# soc_debugss_dssm_mdb_secure register map
Vendor: Texas Instruments
Peripheral module from a debugger description file (folder CC35X1E).
Registers are 32-bit, read-only, reset 0x0 unless marked. A register's access mark holds for its fields unless they carry their own. Offsets are as the file gives them; lines under a group give offsets from that group; [hi:lo] are bit positions; {n}, {i} and the like mark numbered series; 'fields as' and 'values as' point back to an identical list; <NAME> marks a mode.

## soc_debugss_dssm_mdb_secure
0x20 dssm_iidx — This register provides the highest priority enabled interrupt index. FFh means no event pending. Interrupt 0h is the highest priority, 1h next highest, and FEh is the least priority. The priority order is fixed. However, users can implement their own prioritization schemes using other registers that expose the full set of interrupts that have occurred. On each read, only one interrupt is indicated. On a read, the current interrupt (highest priority) is automatically cleared by the hardware and the corresponding interrupt flag in the RIS and MIS are cleared as well. After a read from the CPU (not from the debug interface), the register must be updated with the next highest priority interrupt, if none are pending, then it displays FFh.
  [1:0] STAT — Interrupt index status
    0=NO_INTR (No pending interrupt request); 1=MSG_PEND (TX interrupt); 2=MSG_TAKEN (RX interrupt)
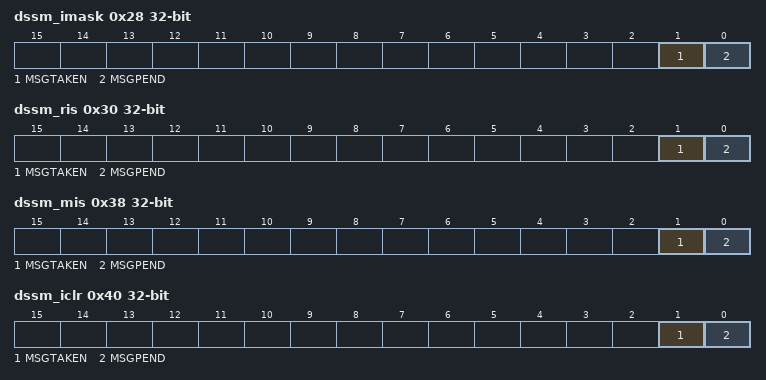
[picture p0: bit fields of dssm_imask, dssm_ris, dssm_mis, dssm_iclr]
0x28 dssm_imask access per field — Interrupt Mask. If a bit is set, then corresponding interrupt is un-masked. Un-masking the interrupt causes the raw interrupt to be visible in IIDX, as well as MIS.
  [1] MSGTAKEN rw — Masks MSG_TAKEN in MIS register
    0=CLR (Interrupt is masked out); 1=SET (Interrupt will request an interrupt service routine and corresponding bit in MIS will be set)
  [0] MSGPEND rw — Masks MSG_PEND in MIS register
    values as MSGTAKEN
0x30 dssm_ris — Raw Interrupt Status. Reflects all pending interrupts, regardless of masking. The RIS register allows the user to implement a poll scheme. A flag set in this register can be cleared by writing 1 to the ICLR register bit even if the corresponding IMASK bit is not enabled.
  [1] MSGTAKEN — Raw interrupt status for MSG_TAKEN
    1=SET (MSG_TAKEN occurred); 0=CLR (MSG_TAKEN did not occur)
  [0] MSGPEND — Raw interrupt status for MSG_PEND
    1=SET (MSG_PEND occurred); 0=CLR (MSG_PEND did not occur)
0x38 dssm_mis — Masked Interrupt Status. This is an AND of the IMASK and RIS registers.
  [1] MSGTAKEN — Masked interrupt status for MSG_TAKEN
    1=SET (MSG_TAKEN requests an interrupt service routine); 0=CLR (MSG_TAKEN did not request an interrupt service routine)
  [0] MSGPEND — Masked interrupt status for MSG_PEND
    1=SET (MSG_PEND requests an interrupt service routine); 0=CLR (MSG_PEND did not request an interrupt service routine)
0x40 dssm_iclr access per field — Interrupt Clear. Write a 1 to clear corresponding Interrupt.
  [1] MSGTAKEN wo — Clears MSG_TAKEN_WROPT in RIS register
    1=CLR (RIS bit corresponding to MSG_TAKEN is cleared); 0=NO_EFFECT (Writing a 0 has no effect)
  [0] MSGPEND wo — Clears MSG_PEND_WROPT in RIS register
    1=CLR (RIS bit corresponding to MSG_PEND is cleared); 0=NO_EFFECT (Writing a 0 has no effect)
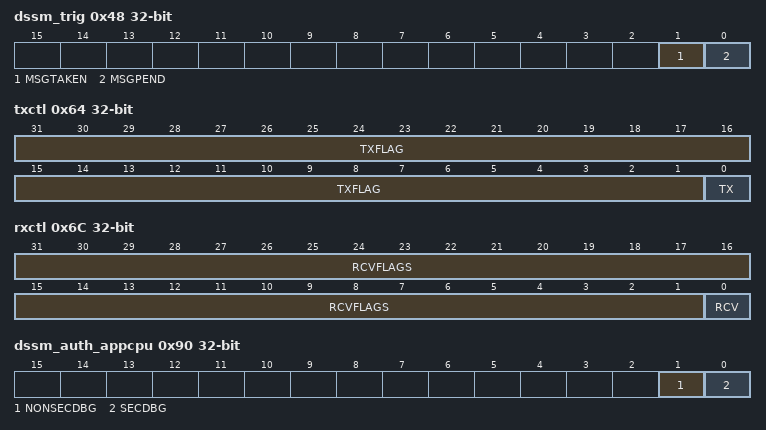
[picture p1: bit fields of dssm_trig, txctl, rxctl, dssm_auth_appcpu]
0x48 dssm_trig access per field — Interrupt Set. Allows interrupts to be set by software (useful in diagnostics and safety checks). Writing a 1 to a bit in ISET will set the event and therefore the related RIS bit also gets set. If the interrupt is enabled through the mask, then the corresponding MIS bit is also set.
  [1] MSGTAKEN wo — Sets MSG_TAKEN_WROPT in RIS register
    1=SET (RIS bit corresponding to MSG_TAKEN is set); 0=NO_EFFECT (Writing a 0 has no effect)
  [0] MSGPEND wo — Sets MSG_PEND_WROPT in RIS register
    1=SET (RIS bit corresponding to MSG_PEND is set); 0=NO_EFFECT (Writing a 0 has no effect)
0x60 txd — This register is used for data transfers from external debug tools to the DSSM module. With the first write access to this register after power cycle a system reset request is issued. The first write to this register after RESET_ALL will trigger a SYSRST request being asserted for one (or as many as required by the system) clock cycle.
  [31:0] TXDATA — Contains data written by an external debug tool to the SEC-AP TXDATA register
0x64 txctl — Transmit control register
  [31:1] TXFLAG — Generic TX flags that can be set by external debug tool. Functionality is defined by SW.
  [0] TX — Indicates data request in DSSM.TXD, set on write via Debug AP to DSSM.TXD. A read of the DSSM.TXD register by SM/OW will clear the TX field. The tool can check that TXD is empty by reading this field. When this flag is 1, a debug request to the SM/OW controller is asserted. If the command starts with 0xAA, the interrupt goes to the SM (or the OW if there is no SM) and if starts with 0x55, it always goes to the OW (going to AT-TEST authentication).
    0=EMPTY (TXD is empty); 1=FULL (TXD is full)
0x68 rxd rw — Receive data register. This register contains the data received from SM/OW. This data is read by external debug tool.
  [31:0] RXDATA — Contains data written by SM/OW.
0x6C rxctl access per field — Receive control register
  [31:1] RCVFLAGS rw — Generic RX flags that can be set by SW and read by external debug tool. Functionality is defined by SW.
  [0] RCV ro — Indicates SM/OW write to the DSSM.RXD register. A read of the DSSM.RXD register by SWD (JTAG) Access Port will clear the RX field.
    0=EMPTY (RXD empty); 1=FULL (RXD full)
0x90 dssm_auth_appcpu — This register is used to control SEC_DBG, NONSEC_DBG, SPIDEN, and SPNONSEC_DBG of Application APPCPU. SEC_DBG, NONSEC_DBG are further processed by DSW based on Active and Debug IPF ID.
  [1] NONSECDBG — Controls non-invasive debug enable. NONSEC_DBG is further processed by DSW based on Active and Debug IPF ID.
    0=DISABLE (Non-invasive debug disabled); 1=ENABLE (Non-invasive debug enabled)
  [0] SECDBG — Controls invasive debug enable. SEC_DBG is further processed by DSW based on Active and Debug IPF ID.
    0=DISABLE (Invasive debug disabled); 1=ENABLE (Invasive debug enabled)
0xA0 dssm_auth_core — This register is used to control SEC_DBG, NONSEC_DBG, SPIDEN, and SPNONSEC_DBG of Application CORE. SEC_DBG, NONSEC_DBG are further processed by DSW based on Active and Debug IPF ID.
  [0] DBG — Controls invasive debug enable. DBG is further processed by DSW based on Active and Debug IPF ID.
    values as dssm_auth_appcpu.SECDBG
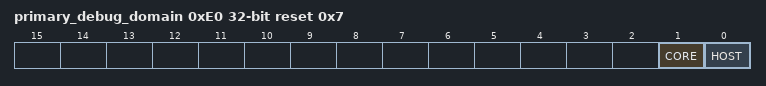
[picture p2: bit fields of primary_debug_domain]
0xE0 primary_debug_domain access per field reset 0x7 — This register is to select the primary debug domain. Whichever domain is selected as primary gets powered up by writing onto csyspwrupreq bit
  [1] CORE rw — Set this bit to 1 if core is to be selected as primary debug domain
  [0] HOST rw — Set this bit to 1 if host is to be selected as primary debug domain
